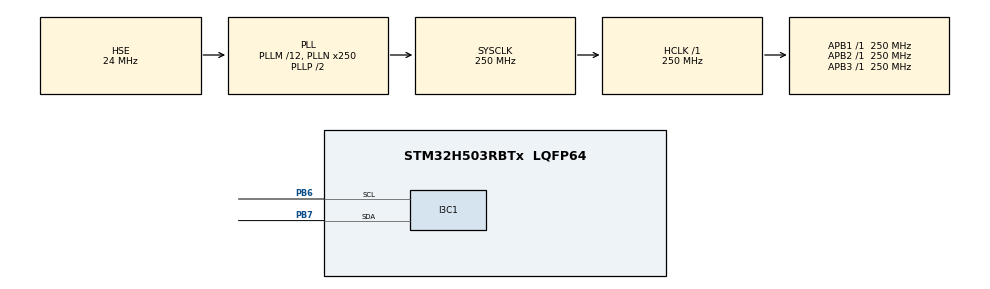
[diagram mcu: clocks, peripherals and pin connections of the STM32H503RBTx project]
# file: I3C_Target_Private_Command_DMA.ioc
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BOOTPATH.BootPathName=LEGACY
BOOTPATH.UserSelectedBootPath=LEGACY
GPDMA1.DESTINC_GPDMACH0=DMA_DINC_INCREMENTED
GPDMA1.DIRECTION_GPDMACH0=DMA_PERIPH_TO_MEMORY
GPDMA1.DIRECTION_GPDMACH1=DMA_MEMORY_TO_PERIPH
GPDMA1.IPHANDLE_GPDMACH0-SIMPLEREQUEST_GPDMACH0=__NULL
GPDMA1.IPHANDLE_GPDMACH1-SIMPLEREQUEST_GPDMACH1=__NULL
GPDMA1.REQUEST_GPDMACH0=GPDMA1_REQUEST_I3C1_RX
GPDMA1.REQUEST_GPDMACH1=GPDMA1_REQUEST_I3C1_TX
GPDMA1.SRCINC_GPDMACH1=DMA_SINC_INCREMENTED
I3C1.IBIPayloadSize=HAL_I3C_PAYLOAD_EMPTY
I3C1.Identifier=0xC6
I3C1.MIPIIdentifier=DEVICE_ID
I3C1.MaxReadDataSize=0xFF
I3C1.MaxWriteDataSize=0xFF
I3C1.RXFIFOThreshold=HAL_I3C_RXFIFO_THRESHOLD_1_4
I3C1.Register1=0x000000f8
I3C1.TXFIFOThreshold=HAL_I3C_TXFIFO_THRESHOLD_1_4
I3C1.hexBusAvailableDuration=0xf8
Mcu.Family=STM32H5
Mcu.Name=STM32H503RBTx
Mcu.Package=LQFP64
Mcu.UserConstants=DEVICE_ID,0x01
NVIC.GPDMA1_Channel0_IRQn=true\:0\:0\:false\:false\:true\:false\:true\:true
NVIC.GPDMA1_Channel1_IRQn=true\:0\:0\:false\:false\:true\:false\:true\:true
NVIC.I3C1_ER_IRQn=true\:0\:0\:false\:false\:true\:true\:true\:true
NVIC.I3C1_EV_IRQn=true\:0\:0\:false\:false\:true\:true\:true\:true
NVIC.PriorityGroup=NVIC_PRIORITYGROUP_4
PB6.Mode=Target
PB6.Signal=I3C1_SCL
PB7.Mode=Target
PB7.Signal=I3C1_SDA
PH0-OSC_IN(PH0).Mode=HSE-External-Oscillator
PH0-OSC_IN(PH0).Signal=RCC_OSC_IN
PH1-OSC_OUT(PH1).Mode=HSE-External-Oscillator
PH1-OSC_OUT(PH1).Signal=RCC_OSC_OUT
ProjectManager.HeapSize=0x200
ProjectManager.StackSize=0x400
ProjectManager.TargetToolchain=EWARM V9.20
RCC.ADCFreq_Value=250000000
RCC.AHBFreq_Value=250000000
RCC.APB1Freq_Value=250000000
RCC.APB1TimFreq_Value=250000000
RCC.APB2Freq_Value=250000000
RCC.APB2TimFreq_Value=250000000
RCC.APB3Freq_Value=250000000
RCC.CSI_VALUE=4000000
RCC.CortexFreq_Value=250000000
RCC.EPOD_VALUE=24000000
RCC.HCLKFreq_Value=250000000
RCC.HSE_VALUE=24000000
RCC.HSI48_VALUE=48000000
RCC.HSIDiv=RCC_HSI_DIV1
RCC.HSI_VALUE=64000000
RCC.LSE_VALUE=32768
RCC.LSIRC_VALUE=32000
RCC.PLL1R=1
RCC.PLL2FRACN=0
RCC.PLLFRACN=0
RCC.PLLM=12
RCC.PLLN=250
RCC.PLLSourceVirtual=RCC_PLL1_SOURCE_HSE
RCC.PWR_Regulator_Voltage_Scale=PWR_REGULATOR_VOLTAGE_SCALE0
RCC.SYSCLKFreq_VALUE=250000000
RCC.SYSCLKSource=RCC_SYSCLKSOURCE_PLLCLK
RCC.USBFreq_Value=48000000
RCC.VCOOutputFreq_Value=500000000
VP_BOOTPATH_VS_BOOTPATH.Mode=BP_Activate
VP_CORTEX_M33_NS_VS_Hclk.Mode=Hclk_Mode
VP_GPDMA1_VS_GPDMACH0.Mode=SIMPLEREQUEST_GPDMACH0
VP_GPDMA1_VS_GPDMACH1.Mode=SIMPLEREQUEST_GPDMACH1
VP_ICACHE_VS_ICACHE.Mode=DefaultMode
VP_MEMORYMAP_VS_MEMORYMAP.Mode=CurAppReg
VP_PWR_VS_DBSignals.Mode=DisableDeadBatterySignals
VP_PWR_VS_LPOM.Mode=PowerOptimisation
VP_PWR_VS_SECSignals.Mode=Security/Privilege
board=custom

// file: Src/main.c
/* USER CODE BEGIN Header */
/**
  ******************************************************************************
  * @file    I3C/I3C_Target_Private_Command_DMA/Src/main.c
  * @author  MCD Application Team
  * @brief   This sample code shows how to use STM32H5xx I3C HAL API as Target
  *          to receive and transmit a data buffer
  *          with a communication process based on DMA transfer.
  *          The communication is done using 2 Boards.
  ******************************************************************************
  * @attention
  *
  * Copyright (c) 2023 STMicroelectronics.
  * All rights reserved.
  *
  * This software is licensed under terms that can be found in the LICENSE file
  * in the root directory of this software component.
  * If no LICENSE file comes with this software, it is provided AS-IS.
  *
  ******************************************************************************
  */
/* USER CODE END Header */
#include "main.h"

I3C_HandleTypeDef hi3c1;
DMA_HandleTypeDef handle_GPDMA1_Channel1;
DMA_HandleTypeDef handle_GPDMA1_Channel0;

/* USER CODE BEGIN PV */
/* Context buffer related to Frame context, contain different buffer value for a communication */
I3C_XferTypeDef aContextBuffers;

/* Variable used to catch completion of Dynamic address assignment procedure */
__IO uint8_t ubDynamicAddressCplt = 0;

/* Buffer used for transmission */
uint8_t aTxBuffer[] = " ****I3C_TwoBoards communication based on DMA****  ****I3C_TwoBoards communication based on DMA****  ****I3C_TwoBoards communication based on DMA**** ";

/* Buffer used for reception */
uint8_t aRxBuffer[RXBUFFERSIZE];
/* USER CODE END PV */

void SystemClock_Config(void);
static void MX_GPIO_Init(void);
static void MX_GPDMA1_Init(void);
static void MX_I3C1_Init(void);
static void MX_ICACHE_Init(void);
/* USER CODE BEGIN PFP */
static uint16_t Buffercmp(uint8_t *pBuffer1, uint8_t *pBuffer2, uint16_t BufferLength);
/* USER CODE END PFP */

int main(void)
{

  /* MCU Configuration--------------------------------------------------------*/

  /* Reset of all peripherals, Initializes the Flash interface and the Systick. */
  HAL_Init();

  /* Configure the system clock */
  SystemClock_Config();

  /* Initialize all configured peripherals */
  MX_GPIO_Init();
  MX_GPDMA1_Init();
  MX_I3C1_Init();
  MX_ICACHE_Init();
  /* USER CODE BEGIN 2 */
  /* Configure LED2 */
  BSP_LED_Init(LED2);

  /*##- Start the listen mode process ####################################*/
  /* Activate notifications for specially for this example
     - Dynamic address association */
  if (HAL_I3C_ActivateNotification(&hi3c1, NULL, HAL_I3C_IT_DAUPDIE) != HAL_OK)
  {
      /* Error_Handler() function is called when error occurs. */
      Error_Handler();
  }

  /*##- Wait for the end of the transfer #################################*/
  /*  Before starting a new communication transfer, you need to check the
  end of current transfer before starting a new one.
  For simplicity reasons, this example is just waiting till the end of the
  transfer, but application may perform other tasks while transfer operation
  is ongoing. */
  while (ubDynamicAddressCplt != 1)
  {
  }

  /*##- Start the reception process ######################################*/

  /* Set user buffer information for target receive data */
  aContextBuffers.RxBuf.pBuffer = aRxBuffer;
  aContextBuffers.RxBuf.Size    = RXBUFFERSIZE;
  aContextBuffers.TxBuf.pBuffer = aTxBuffer;
  aContextBuffers.TxBuf.Size    = TXBUFFERSIZE;

  /* Receive private data processus */
  if (HAL_I3C_Tgt_Receive_DMA(&hi3c1, &aContextBuffers) !=  HAL_OK)
  {
    /* Error_Handler() function is called when error occurs. */
    Error_Handler();
  }

  /*##- Wait for the end of the transfer #################################*/
  /*  Before starting a new communication transfer, you need to check the current
  state of the peripheral; if it's busy you need to wait for the end of current
  transfer before starting a new one.
  For simplicity reasons, this example is just waiting till the end of the
  transfer, but application may perform other tasks while transfer operation
  is ongoing. */
  while (HAL_I3C_GetState(&hi3c1) != HAL_I3C_STATE_LISTEN)
  {
  }

  /*##- Start the transmission process ###################################*/
  /* Transmit private data processus */
  if (HAL_I3C_Tgt_Transmit_DMA(&hi3c1, &aContextBuffers) !=  HAL_OK)
  {
    /* Error_Handler() function is called when error occurs. */
    Error_Handler();
  }

  /*##- Wait for the end of the transfer #################################*/
  /*  Before starting a new communication transfer, you need to check the current
  state of the peripheral; if it's busy you need to wait for the end of current
  transfer before starting a new one.
  For simplicity reasons, this example is just waiting till the end of the
  transfer, but application may perform other tasks while transfer operation
  is ongoing. */
  while (HAL_I3C_GetState(&hi3c1) != HAL_I3C_STATE_LISTEN)
  {
  }

  /*##- Compare the sent and received buffers ############################*/
  if (Buffercmp((uint8_t *)aTxBuffer, (uint8_t *)aRxBuffer, RXBUFFERSIZE))
  {
    /* Processing Error */
    Error_Handler();
  }
  /* USER CODE END 2 */

  /* Infinite loop */
  while (1)
  {

  }
}

void SystemClock_Config(void)
{
  RCC_OscInitTypeDef RCC_OscInitStruct = {0};
  RCC_ClkInitTypeDef RCC_ClkInitStruct = {0};

  /** Configure the main internal regulator output voltage
  */
  __HAL_PWR_VOLTAGESCALING_CONFIG(PWR_REGULATOR_VOLTAGE_SCALE0);

  while(!__HAL_PWR_GET_FLAG(PWR_FLAG_VOSRDY)) {}

  /** Initializes the RCC Oscillators according to the specified parameters
  * in the RCC_OscInitTypeDef structure.
  */
  RCC_OscInitStruct.OscillatorType = RCC_OSCILLATORTYPE_HSE;
  RCC_OscInitStruct.HSEState = RCC_HSE_ON;
  RCC_OscInitStruct.PLL.PLLState = RCC_PLL_ON;
  RCC_OscInitStruct.PLL.PLLSource = RCC_PLL1_SOURCE_HSE;
  RCC_OscInitStruct.PLL.PLLM = 12;
  RCC_OscInitStruct.PLL.PLLN = 250;
  RCC_OscInitStruct.PLL.PLLP = 2;
  RCC_OscInitStruct.PLL.PLLQ = 2;
  RCC_OscInitStruct.PLL.PLLR = 1;
  RCC_OscInitStruct.PLL.PLLRGE = RCC_PLL1_VCIRANGE_1;
  RCC_OscInitStruct.PLL.PLLVCOSEL = RCC_PLL1_VCORANGE_WIDE;
  RCC_OscInitStruct.PLL.PLLFRACN = 0;
  if (HAL_RCC_OscConfig(&RCC_OscInitStruct) != HAL_OK)
  {
    Error_Handler();
  }

  /** Initializes the CPU, AHB and APB buses clocks
  */
  RCC_ClkInitStruct.ClockType = RCC_CLOCKTYPE_HCLK|RCC_CLOCKTYPE_SYSCLK
                              |RCC_CLOCKTYPE_PCLK1|RCC_CLOCKTYPE_PCLK2
                              |RCC_CLOCKTYPE_PCLK3;
  RCC_ClkInitStruct.SYSCLKSource = RCC_SYSCLKSOURCE_PLLCLK;
  RCC_ClkInitStruct.AHBCLKDivider = RCC_SYSCLK_DIV1;
  RCC_ClkInitStruct.APB1CLKDivider = RCC_HCLK_DIV1;
  RCC_ClkInitStruct.APB2CLKDivider = RCC_HCLK_DIV1;
  RCC_ClkInitStruct.APB3CLKDivider = RCC_HCLK_DIV1;

  if (HAL_RCC_ClockConfig(&RCC_ClkInitStruct, FLASH_LATENCY_5) != HAL_OK)
  {
    Error_Handler();
  }

  /** Configure the programming delay
  */
  __HAL_FLASH_SET_PROGRAM_DELAY(FLASH_PROGRAMMING_DELAY_2);
}

static void MX_GPDMA1_Init(void)
{

  /* Peripheral clock enable */
  __HAL_RCC_GPDMA1_CLK_ENABLE();

  /* GPDMA1 interrupt Init */
    HAL_NVIC_SetPriority(GPDMA1_Channel0_IRQn, 0, 0);
    HAL_NVIC_EnableIRQ(GPDMA1_Channel0_IRQn);
    HAL_NVIC_SetPriority(GPDMA1_Channel1_IRQn, 0, 0);
    HAL_NVIC_EnableIRQ(GPDMA1_Channel1_IRQn);

}

static void MX_I3C1_Init(void)
{

  I3C_FifoConfTypeDef sFifoConfig = {0};
  I3C_TgtConfTypeDef sTgtConfig = {0};

  hi3c1.Instance = I3C1;
  hi3c1.Mode = HAL_I3C_MODE_TARGET;
  hi3c1.Init.TgtBusCharacteristic.BusAvailableDuration = 0xf8;
  if (HAL_I3C_Init(&hi3c1) != HAL_OK)
  {
    Error_Handler();
  }

  /** Configure FIFO
  */
  sFifoConfig.RxFifoThreshold = HAL_I3C_RXFIFO_THRESHOLD_1_4;
  sFifoConfig.TxFifoThreshold = HAL_I3C_TXFIFO_THRESHOLD_1_4;
  sFifoConfig.ControlFifo = HAL_I3C_CONTROLFIFO_DISABLE;
  sFifoConfig.StatusFifo = HAL_I3C_STATUSFIFO_DISABLE;

  if (HAL_I3C_SetConfigFifo(&hi3c1, &sFifoConfig) != HAL_OK)
  {
    Error_Handler();
  }

  /** Configure Target
  */
  sTgtConfig.Identifier = 0xC6;
  sTgtConfig.MIPIIdentifier = DEVICE_ID;
  sTgtConfig.CtrlRoleRequest = DISABLE;
  sTgtConfig.HotJoinRequest = DISABLE;
  sTgtConfig.IBIRequest = DISABLE;
  sTgtConfig.IBIPayload = DISABLE;
  sTgtConfig.IBIPayloadSize = HAL_I3C_PAYLOAD_EMPTY;
  sTgtConfig.MaxReadDataSize = 0xFF;
  sTgtConfig.MaxWriteDataSize = 0xFF;
  sTgtConfig.CtrlCapability = DISABLE;
  sTgtConfig.GroupAddrCapability = DISABLE;
  sTgtConfig.DataTurnAroundDuration = HAL_I3C_TURNAROUND_TIME_TSCO_LESS_12NS;
  sTgtConfig.MaxReadTurnAround = 0;
  sTgtConfig.MaxDataSpeed = HAL_I3C_GETMXDS_FORMAT_1;
  sTgtConfig.MaxSpeedLimitation = DISABLE;
  sTgtConfig.HandOffActivityState = HAL_I3C_HANDOFF_ACTIVITY_STATE_0;
  sTgtConfig.HandOffDelay = DISABLE;
  sTgtConfig.PendingReadMDB = DISABLE;
  if (HAL_I3C_Tgt_Config(&hi3c1, &sTgtConfig) != HAL_OK)
  {
    Error_Handler();
  }

}

static void MX_ICACHE_Init(void)
{

  /** Enable instruction cache (default 2-ways set associative cache)
  */
  if (HAL_ICACHE_Enable() != HAL_OK)
  {
    Error_Handler();
  }

}

static void MX_GPIO_Init(void)
{

  /* GPIO Ports Clock Enable */
  __HAL_RCC_GPIOH_CLK_ENABLE();
  __HAL_RCC_GPIOB_CLK_ENABLE();

}

/* USER CODE BEGIN 4 */
/**
  * @brief I3C notify callback after receiving a notification.
  *        The main objective of this user function is to check on the notification ID and assign 1 to the global
  *        variable used to indicate that the event is well finished.
  * @par Called functions
  * - HAL_I3C_NotifyCallback()
  * @retval None
  */
void HAL_I3C_NotifyCallback(I3C_HandleTypeDef *hi3c, uint32_t eventId)
{
  if ((eventId & EVENT_ID_DAU) == EVENT_ID_DAU)
  {
    ubDynamicAddressCplt = 1;
  }
  else
  {
    /* Error_Handler() function is called when error occurs. */
    Error_Handler();
  }
}

/**
  * @brief  Target Reception Complete callback.
  * @param  hi3c : [IN] Pointer to an I3C_HandleTypeDef structure that contains the configuration information
  *                     for the specified I3C.
  * @retval None
  */
void HAL_I3C_TgtRxCpltCallback(I3C_HandleTypeDef *hi3c)
{
  /* Toggle LED2: Transfer in Reception process is correct */
  BSP_LED_Toggle(LED2);
}

/**
  * @brief  Target Transmit Complete callback.
  * @param  hi3c : [IN] Pointer to an I3C_HandleTypeDef structure that contains the configuration information
  *                     for the specified I3C.
  * @retval None
  */
void HAL_I3C_TgtTxCpltCallback(I3C_HandleTypeDef *hi3c)
{
  /* Toggle LED2: Transfer in transmission process is correct */
  BSP_LED_Toggle(LED2);
}

/**
  * @brief  Error callback.
  * @param  hi3c : [IN] Pointer to an I3C_HandleTypeDef structure that contains the configuration information
  *                     for the specified I3C.
  * @retval None
  */
void HAL_I3C_ErrorCallback(I3C_HandleTypeDef *hi3c)
{
  /* Error_Handler() function is called when error occurs. */
  Error_Handler();
}

/**
  * @brief  Compares two buffers.
  * @param  pBuffer1, pBuffer2: buffers to be compared.
  * @param  BufferLength: buffer's length
  * @retval 0  : pBuffer1 identical to pBuffer2
  *         >0 : pBuffer1 differs from pBuffer2
  */
static uint16_t Buffercmp(uint8_t *pBuffer1, uint8_t *pBuffer2, uint16_t BufferLength)
{
  while (BufferLength--)
  {
    if ((*pBuffer1) != *pBuffer2)
    {
      return BufferLength;
    }
    pBuffer1++;
    pBuffer2++;
  }

  return 0;
}

/* USER CODE END 4 */

void Error_Handler(void)
{
  /* USER CODE BEGIN Error_Handler_Debug */
  /* Error if LED2 is slowly blinking (1 sec. period) */
  while (1)
  {
    BSP_LED_Toggle(LED2);
    HAL_Delay(1000);
  }
  /* USER CODE END Error_Handler_Debug */
}
